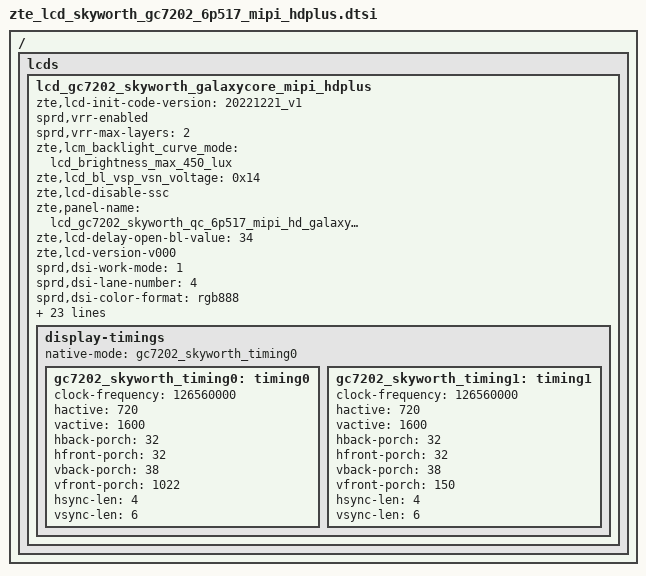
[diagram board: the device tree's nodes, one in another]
/ {
	fragment {
		target-path = "/";
		__overlay__ {
			lcds {
				lcd_gc7202_skyworth_galaxycore_mipi_hdplus: lcd_gc7202_skyworth_galaxycore_mipi_hdplus {
					zte,lcd-init-code-version = "20221221_v1";
					sprd,vrr-enabled;
					sprd,vrr-max-layers = <2>;
					zte,lcm_backlight_curve_mode = "lcd_brightness_max_450_lux";
					zte,lcd_bl_vsp_vsn_voltage = <0x14>;
					zte,lcd-disable-ssc;
					zte,panel-name = "lcd_gc7202_skyworth_qc_6p517_mipi_hd_galaxycore_4lane";
					zte,lcd-delay-open-bl-value = <34>;
					zte,lcd-version-v000;

					sprd,dsi-work-mode = <1>;
					sprd,dsi-lane-number = <4>;
					sprd,dsi-color-format = "rgb888";

					sprd,dpi-clk-div = <8>;
					sprd,video-lp-cmd-enable = <1>;
					sprd,hporch-lp-disable = <1>;

					sprd,phy-bit-clock = <1012480>;
					sprd,phy-escape-clock = <20000>;/* kHz */

					sprd,width-mm = <67932>;
					sprd,height-mm = <150960>;

					sprd,esd-check-enable = <1>;/* 0:close , 1:open */
					sprd,esd-check-mode = <1>;/* 0:REG ,1:TE  */
					sprd,esd-check-period = <2000>;
					sprd,esd-check-register = <0x0A>;
					sprd,esd-check-value = <0x9C>;

		sprd,reset-on-sequence = <1 50>, <0 50>, <1 120>;
		sprd,reset-off-sequence = <1 10>;

					sprd,use-dcs-write;
		sprd,initial-command = [39 00 00 04 FF 55 AA 66
					15 00 00 02 FF B3
					15 00 00 02 2B 0C
					15 00 00 02 29 3F
					15 00 00 02 28 C0
					15 00 00 02 2A 03
					15 00 00 02 68 0F
					15 00 00 02 FF 20
					15 00 00 02 FB 00
					15 00 00 02 FF 21
					15 00 00 02 FB 00
					15 00 00 02 FF 22
					15 00 00 02 FB 00
					15 00 00 02 FF 23
					15 00 00 02 FB 00
					15 00 00 02 FF 24
					15 00 00 02 FB 00
					15 00 00 02 FF 27
					15 00 00 02 FB 00
					15 00 00 02 FF 28
					15 00 00 02 FB 00
					15 00 00 02 FF B3
					15 00 00 02 FB 00
					15 00 00 02 FF 10
					15 00 00 02 FB 00
					15 00 00 02 FF 28
					15 00 00 02 53 44
					15 00 00 02 50 4C
					15 00 00 02 52 53
					15 00 00 02 4D A2
					15 00 00 02 FF 20
					15 00 00 02 A5 00
					15 00 00 02 A6 FF
					15 00 00 02 A9 00
					15 00 00 02 AA FF
					15 00 00 02 D3 06
					15 00 00 02 2D 1F
					15 00 00 02 2E 42
					15 00 00 02 2F 14
					15 00 00 02 FF 22
					15 00 00 02 1F 06
					15 00 00 02 FF B3
					15 00 00 02 3E 03
					15 00 00 02 58 84
					15 00 00 02 53 1A
					15 00 00 02 82 1A
					15 00 00 02 78 01
					15 00 00 02 FF B3
					15 00 00 02 4A 0F
					15 00 00 02 7D 80
					15 00 00 02 5B 4B
					15 00 00 02 48 26
					15 00 00 02 7C 8C
					15 00 00 02 FF 20
					15 00 00 02 A3 4A
					15 00 00 02 A7 4A
					15 00 00 02 FF B3
					15 00 00 02 3F 37
					15 00 00 02 5E 10
					15 00 00 02 FF 10
					39 00 00 03 71 12 02
					15 00 00 02 FF 22
					15 00 00 02 E4 00
					15 00 00 02 01 06
					15 00 00 02 02 40
					15 00 00 02 25 02
					15 00 00 02 26 00
					15 00 00 02 2E B4
					15 00 00 02 2F 00
					15 00 00 02 36 03
					15 00 00 02 37 00
					15 00 00 02 3F B4
					15 00 00 02 40 00
					15 00 00 02 DC 00
					15 00 00 02 E0 01
					15 00 00 02 FF 28
					15 00 00 02 01 25
					15 00 00 02 02 19
					15 00 00 02 03 1E
					15 00 00 02 04 23
					15 00 00 02 05 00
					15 00 00 02 06 02
					15 00 00 02 07 18
					15 00 00 02 08 22
					15 00 00 02 09 0C
					15 00 00 02 0A 0E
					15 00 00 02 0B 08
					15 00 00 02 0C 0A
					15 00 00 02 0D 25
					15 00 00 02 0E 25
					15 00 00 02 0F 25
					15 00 00 02 10 25
					15 00 00 02 11 25
					15 00 00 02 12 25
					15 00 00 02 13 25
					15 00 00 02 14 25
					15 00 00 02 15 25
					15 00 00 02 16 25
					15 00 00 02 17 25
					15 00 00 02 18 19
					15 00 00 02 19 1E
					15 00 00 02 1A 23
					15 00 00 02 1B 01
					15 00 00 02 1C 03
					15 00 00 02 1D 18
					15 00 00 02 1E 22
					15 00 00 02 1F 0D
					15 00 00 02 20 0F
					15 00 00 02 21 09
					15 00 00 02 22 0B
					15 00 00 02 23 25
					15 00 00 02 24 25
					15 00 00 02 25 25
					15 00 00 02 26 25
					15 00 00 02 27 25
					15 00 00 02 28 25
					15 00 00 02 29 25
					15 00 00 02 2A 25
					15 00 00 02 2B 25
					15 00 00 02 2D 25
					15 00 00 02 30 00
					15 00 00 02 31 00
					15 00 00 02 34 00
					15 00 00 02 35 00
					15 00 00 02 36 00
					15 00 00 02 37 00
					15 00 00 02 2F 03
					15 00 00 02 FF 21
					15 00 00 02 7E 03
					15 00 00 02 7F 23
					15 00 00 02 8B 23
					15 00 00 02 80 07
					15 00 00 02 8C 03
					15 00 00 02 81 03
					15 00 00 02 8D 07
					15 00 00 02 AF 40
					15 00 00 02 B0 40
					15 00 00 02 83 02
					15 00 00 02 8F 02
					15 00 00 02 84 1A
					15 00 00 02 90 1A
					15 00 00 02 85 55
					15 00 00 02 91 55
					15 00 00 02 87 02
					15 00 00 02 93 06
					15 00 00 02 82 B0
					15 00 00 02 8E B0
					15 00 00 02 2B 00
					15 00 00 02 2E 03
					15 00 00 02 88 A7
					15 00 00 02 89 22
					15 00 00 02 8A 33
					15 00 00 02 94 A7
					15 00 00 02 95 22
					15 00 00 02 96 33
					15 00 00 02 45 0F
					15 00 00 02 46 B3
					15 00 00 02 4C B3
					15 00 00 02 52 B3
					15 00 00 02 58 B3
					15 00 00 02 47 0A
					15 00 00 02 4D 09
					15 00 00 02 53 08
					15 00 00 02 59 07
					15 00 00 02 48 07
					15 00 00 02 4E 08
					15 00 00 02 54 09
					15 00 00 02 5A 0A
					15 00 00 02 76 40
					15 00 00 02 77 40
					15 00 00 02 78 40
					15 00 00 02 79 40
					15 00 00 02 49 1A
					15 00 00 02 4A 55
					15 00 00 02 4F 1A
					15 00 00 02 50 55
					15 00 00 02 55 1A
					15 00 00 02 56 55
					15 00 00 02 5B 1A
					15 00 00 02 5C 55
					15 00 00 02 BE 03
					15 00 00 02 C0 74
					15 00 00 02 C1 70
					15 00 00 02 BF BB
					15 00 00 02 B3 A5
					15 00 00 02 B4 0B
					15 00 00 02 B5 25
					15 00 00 02 B6 0B
					15 00 00 02 BB 0B
					15 00 00 02 BC 40
					15 00 00 02 FF 22
					15 00 00 02 05 10
					15 00 00 02 08 10
					15 00 00 02 0F 01
					15 00 00 02 FF 20
					15 00 00 02 25 12
					15 00 00 02 FF 20
					15 00 00 02 C3 00
					15 00 00 02 C4 66
					15 00 00 02 C5 00
					15 00 00 02 C6 66
					15 00 00 02 B3 00
					15 00 00 02 B4 32
					15 00 00 02 B5 00
					15 00 00 02 B6 DC
					15 00 00 02 FF 28
					15 00 00 02 3D 47
					15 00 00 02 3E 47
					15 00 00 02 3F 5c
					15 00 00 02 40 5c
					15 00 00 02 45 46
					15 00 00 02 46 46
					15 00 00 02 47 5b
					15 00 00 02 48 5b
					15 00 00 02 5A 75
					15 00 00 02 5B 72
					15 00 00 02 FF 20
					15 00 00 02 7E 01
					15 00 00 02 7F 00
					15 00 00 02 80 04
					15 00 00 02 81 00
					15 00 00 02 82 00
					15 00 00 02 83 64
					15 00 00 02 84 64
					15 00 00 02 85 28
					15 00 00 02 86 C3
					15 00 00 02 87 28
					15 00 00 02 88 C3
					15 00 00 02 8A 0A
					15 00 00 02 8B 0A
					15 00 00 02 FF 23
					15 00 00 02 29 03
					39 00 00 11 01 00 00 00 20 00 51 00 73 00 8C 00 A1 00 B7 00 C6
					39 00 00 11 02 00 D7 01 09 01 32 01 70 01 A0 01 EC 02 2D 02 2F
					39 00 00 11 03 02 73 02 C3 02 F4 03 31 03 57 03 84 03 91 03 9F
					39 00 00 0D 04 03 AD 03 BC 03 CD 03 DF 03 F4 03 FF
					39 00 00 11 0D 00 00 00 20 00 51 00 73 00 8C 00 A1 00 B7 00 C6
					39 00 00 11 0E 00 D7 01 09 01 32 01 70 01 A0 01 EC 02 2D 02 2F
					39 00 00 11 0F 02 73 02 C3 02 F4 03 31 03 57 03 84 03 91 03 9F
					39 00 00 0D 10 03 AD 03 BC 03 CD 03 DF 03 F4 03 FF
					15 00 00 02 2D 65//PWM:12bit
					15 00 00 02 2E 00
					15 00 00 02 32 02
					15 00 00 02 33 10//PWM=20KHz
					15 00 00 02 FF 10
					39 00 00 03 51 00 00
					15 00 00 02 53 2C
					15 00 00 02 55 00
					15 00 00 02 36 08
					15 00 00 02 69 00
					15 00 00 02 35 00
					15 00 00 02 FF 24
					15 00 00 02 7D 55
					39 00 00 04 FF 66 99 55
					15 00 00 02 FF 10
					05 78 00 01 11 
					05 14 00 01 29
		
		];

					sprd,sleep-in-command = [
                    //无手势唤醒，VSP、VSN掉电
					39 00 00 04 FF 55 AA 66
					15 00 00 02 FF B3
					15 00 00 02 68 00
					15 00 00 02 2A 00
					15 00 00 02 28 00
					15 00 00 02 29 00
					15 00 00 02 2B 00
					15 00 00 02 FF 20
					15 00 00 02 4A 01
					15 00 00 02 48 10
					15 00 00 02 49 00
					15 00 00 02 FF 10
					15 32 00 02 28 00
					15 78 00 02 10 00
					15 00 00 02 FF 26
					39 00 00 03 1D 8A 80
					15 00 00 02 FF B3
					15 00 00 02 04 16
					15 00 00 02 FF B3
					15 00 00 02 01 90
					15 00 00 02 FF 26
					15 01 00 02 1F 01					
					];
						
							sprd,sleep-in-command2 = [		            
					//有手势唤醒，VSP、VSN不掉电
					39 00 00 04 FF 55 AA 66
					15 00 00 02 FF B3
					15 00 00 02 68 00
					15 00 00 02 2A 00
					15 00 00 02 28 00
					15 00 00 02 29 00
					15 00 00 02 2B 00
					15 00 00 02 FF 20
					15 00 00 02 4A 01
					15 00 00 02 48 10
					15 00 00 02 49 00
					15 00 00 02 FF 10
					15 32 00 02 28 00
					15 78 00 02 10 00
					15 00 00 02 FF 26
					15 00 00 02 FB 00
					15 01 00 02 1F 01
					];
						
					sprd,sleep-out-command = [
						05 78 00 01 11
						05 64 00 01 29
						];

					display-timings {
						native-mode = <&gc7202_skyworth_timing0>;
						gc7202_skyworth_timing0: timing0 {/*60hz*/
							clock-frequency = <126560000>;
							hactive = <720>;
 							vactive = <1600>;
 							hback-porch = <32>;
 							hfront-porch = <32>;
 							vback-porch = <38>;
							vfront-porch = <1022>;
 							hsync-len = <4>;
 							vsync-len = <6>;
 
 						};
						 gc7202_skyworth_timing1: timing1 {/*90hz*/
							clock-frequency = <126560000>;
 							hactive = <720>;
 							vactive = <1600>;
 							hback-porch = <32>;
 							hfront-porch = <32>;
 							vback-porch = <38>;
							vfront-porch = <150>;
 							hsync-len = <4>;
 							vsync-len = <6>;
 
						};
					};
					/*
					oled-backlight {
						default-brightness-level = <1632>;
						sprd,max-level = <4095>;
						brightness-levels = [
							39 00 00 03 51 00 00
							39 00 00 02 53 2C
						];
					};*/
				};
			};
		};
	};
};
